# wiz16b8m4ct3_0_WIZ16B8M4CT3 register map
Vendor: Texas Instruments
Registers are 32-bit, read-write, reset 0x0 unless marked. A register's access mark holds for its fields unless they carry their own. Offsets are as the file gives them; [hi:lo] are bit positions; {n}, {i} and the like mark numbered series.

## wiz16b8m4ct3_0_WIZ16B8M4CT3 (part 4 of 12)
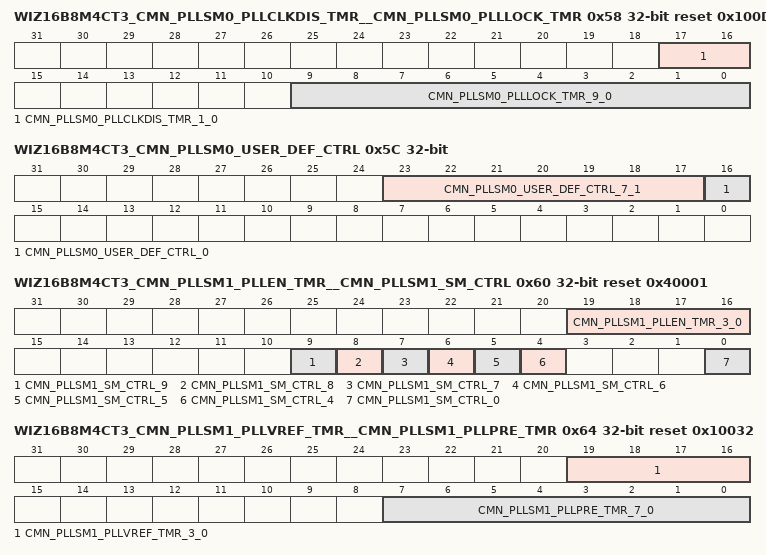
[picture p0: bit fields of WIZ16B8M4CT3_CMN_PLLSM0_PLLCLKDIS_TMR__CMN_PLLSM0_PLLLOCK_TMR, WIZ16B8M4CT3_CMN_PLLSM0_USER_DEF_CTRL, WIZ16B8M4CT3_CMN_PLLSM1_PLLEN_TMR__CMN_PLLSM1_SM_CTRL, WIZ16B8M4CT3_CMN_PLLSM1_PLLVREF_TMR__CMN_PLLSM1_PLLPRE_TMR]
0x58 WIZ16B8M4CT3_CMN_PLLSM0_PLLCLKDIS_TMR__CMN_PLLSM0_PLLLOCK_TMR reset 0x100D1
  [17:16] CMN_PLLSM0_PLLCLKDIS_TMR_1_0 — PLL clock disable delay state timer value : Value used for the timer when the startup state machine is in the PLL clock disable delay state. This timer delay is specified as the number of reference clocks to count.
  [9:0] CMN_PLLSM0_PLLLOCK_TMR_9_0 — PLL lock delay state timer value : Value used for the timer when the startup state machine is in the PLL lock delay state. This timer delay is specified as the number of reference clocks to count.
0x5C WIZ16B8M4CT3_CMN_PLLSM0_USER_DEF_CTRL
  [23:17] CMN_PLLSM0_USER_DEF_CTRL_7_1 — Reserved - spare
  [16] CMN_PLLSM0_USER_DEF_CTRL_0 — PLL lock override: When active (1'b1), this bit will force the PLL lock indication active.
0x60 WIZ16B8M4CT3_CMN_PLLSM1_PLLEN_TMR__CMN_PLLSM1_SM_CTRL reset 0x40001
  [19:16] CMN_PLLSM1_PLLEN_TMR_3_0 — PLL enable state timer value : Value used for the timer when the startup state machine is in the PLL enable state. This timer delay is specified as the number of reference clocks to count.
  [9] CMN_PLLSM1_SM_CTRL_9 — PLL enable override enable : When active (1'b1), the PLL enable override bit in this register will drive the pllsmda_pll_en pin from the PLLSM directly.
  [8] CMN_PLLSM1_SM_CTRL_8 — PLL enable override : When enabled by the PLL enable override enable bit in this register, this bit will drive the pllsmda_pll_en pin from the PLLSM directly.
  [7] CMN_PLLSM1_SM_CTRL_7 — PLL reset override enable : When active (1'b1), the PLL reset override bit in this register will drive the pllsmda_pll_rst_n pin from the PLLSM directly.
  [6] CMN_PLLSM1_SM_CTRL_6 — PLL reset override : When enabled by the PLL reset override enable bit in this register, this bit will drive the pllsmda_pll_rst_n pin from the PLLSM directly.
  [5] CMN_PLLSM1_SM_CTRL_5 — PLL pre charge override enable : When active (1'b1), the PLL pre charge override bit in this register will drive the pllsmda_pll_pre_charge pin from the PLLSM directly.
  [4] CMN_PLLSM1_SM_CTRL_4 — PLL pre charge override : When enabled by the PLL pre charge override enable bit in this register, this bit will drive the pllsmda_pll_pre_charge pin from the PLLSM directly.
  [0] CMN_PLLSM1_SM_CTRL_0 — Skip PLL re-calibration : When this bit is active (1'b1), the PLL calibration state will be skipped if it was previously run, unless the PLL is disabled or resetting the state machine.
0x64 WIZ16B8M4CT3_CMN_PLLSM1_PLLVREF_TMR__CMN_PLLSM1_PLLPRE_TMR reset 0x10032
  [19:16] CMN_PLLSM1_PLLVREF_TMR_3_0 — PLL VREF delay state timer value : Value used for the timer when the startup state machine is in the PLL VREF delay state. This timer delay is specified as the number of reference clocks to count.
  [7:0] CMN_PLLSM1_PLLPRE_TMR_7_0 — PLL pre-charge state timer value : Value used for the timer when the startup state machine is in the PLL pre-charge state. This timer delay is specified as the number of reference clocks to count.
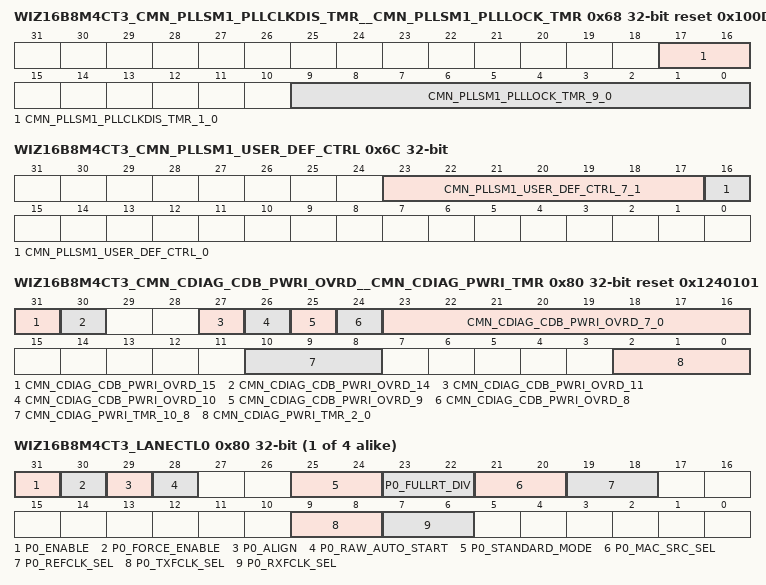
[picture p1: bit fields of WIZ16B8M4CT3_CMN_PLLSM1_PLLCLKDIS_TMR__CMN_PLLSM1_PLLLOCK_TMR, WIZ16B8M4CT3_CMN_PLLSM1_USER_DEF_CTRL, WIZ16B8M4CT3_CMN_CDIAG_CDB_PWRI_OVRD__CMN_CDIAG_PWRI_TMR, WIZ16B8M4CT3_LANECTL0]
0x68 WIZ16B8M4CT3_CMN_PLLSM1_PLLCLKDIS_TMR__CMN_PLLSM1_PLLLOCK_TMR reset 0x100D1
  [17:16] CMN_PLLSM1_PLLCLKDIS_TMR_1_0 — PLL clock disable delay state timer value : Value used for the timer when the startup state machine is in the PLL clock disable delay state. This timer delay is specified as the number of reference clocks to count.
  [9:0] CMN_PLLSM1_PLLLOCK_TMR_9_0 — PLL lock delay state timer value : Value used for the timer when the startup state machine is in the PLL lock delay state. This timer delay is specified as the number of reference clocks to count.
0x6C WIZ16B8M4CT3_CMN_PLLSM1_USER_DEF_CTRL
  [23:17] CMN_PLLSM1_USER_DEF_CTRL_7_1 — Reserved - spare
  [16] CMN_PLLSM1_USER_DEF_CTRL_0 — PLL lock override: When active (1'b1), this bit will force the PLL lock indication active.
0x80 WIZ16B8M4CT3_CMN_CDIAG_CDB_PWRI_OVRD__CMN_CDIAG_PWRI_TMR access per field reset 0x1240101
  [31] CMN_CDIAG_CDB_PWRI_OVRD_15 rw — Power island controller input override enable: When enabled, the power island control state machine input override bits in this register will drive the power island control state machine directly, and override any control from other state machines in the macro. Note: The CDB power island must be triggered to be enabled, by accessing a register outside of the common control module control and diagnostic registers space, prior to enabling this function. Note: This bit must never change state in the same register write that any of the override bits it controls in this register are changed. 1'b0: Override disabled 1'b1: Override enabled
  [30] CMN_CDIAG_CDB_PWRI_OVRD_14 rw — Power island controller output override enable: When enabled, the power island control state machine output override bits in this register will drive the power island control state machine outputs, and override any control from power island control state machine. Note: This bit must never change state in the same register write that any of the override bits it controls in this register are changed. 1'b0: Override disabled 1'b1: Override enabled
  [27] CMN_CDIAG_CDB_PWRI_OVRD_11 rw — Power suspend request override: When enabled, this bit will override the power_suspend_req input of the power island control state machine. Note: Whenever changing the state of this bit, no other CDB register access should be initiated for 1 uSec, to keep the CDB clock off while the power island state change transition is in progress.
  [26] CMN_CDIAG_CDB_PWRI_OVRD_10 ro — Power suspend acknowledge: This is the current state of the power_suspend_ack output from the power island control state machine. Note: This bit will always be set to 1'b1 after the power island is enabled, as a function of the power island controller input override enable bit in this register.
  [25] CMN_CDIAG_CDB_PWRI_OVRD_9 rw — Power recover request override: When enabled, this bit will override the power_recover_req input of the power island control state machine. Note: Whenever changing the state of this bit, no other CDB register access should be initiated for 1 uSec, to keep the CDB clock off while the power island state change transition is in progress.
  [24] CMN_CDIAG_CDB_PWRI_OVRD_8 ro — Power recover acknowledge: This is the current state of the power_recover_ack output from the power island control state machine. Note: This bit will always be set to 1'b1 after the power island is enabled, as a function of the power island controller input override enable bit in this register.
  [23:16] CMN_CDIAG_CDB_PWRI_OVRD_7_0 rw — Power island controller output override: When enabled, the bits in this field will override the output signals from the power island control state machine. The following are the power island control state machine output signals, and the bits in this field that they are associated with. Bit 7: state_sandh Bit 6: state_ret_save Bit 5: state_ret_restore (active low) Bit 4: power_en_ph_1 Bit 3: power_en_ph_2 Bit 2: power_isolation Bit 1: power_por_reset_n Bit 0: power_rstr_reset_n The default value of the bits in this register are such that the power island is not forced to be switched on when the power island controller output override enable bit in this register is enabled. When using this register to switch this power island on and off, the bits in this field are required to change in a specific order with individual register writes. The writes must happen in the order specified below. Note: When using this output override option in conditions when the reference clock is off, the CDB registers on the power island will only be readable, and latency will be much longer. The reason for this is the reference clock is normally used to synchronize control functions associated with this power island. Therefore these control functions will not proceed as they would in normal operation. This results in writes not being capable, and reads completing under the control of the watchdog timer.
  [10:8] CMN_CDIAG_PWRI_TMR_10_8 rw — Power enable phase 2 timer value: This specifies the number of reference clock cycles the power island control state machines in common will wait in the power phase 2 enable states, in order to allow enough time for the second phase of the switched domain to power up, before deactivating the isolation functions. The default value of this register corresponds to a delay of 40 nSec. Note: A value of 0 in this field is not valid, and will result in a delay of 1 clock cycle.
  [2:0] CMN_CDIAG_PWRI_TMR_2_0 rw — Power enable phase 1 timer value: This specifies the number of reference clock cycles the power island control state machines in common will wait in the power phase 1 enable states, in order to allow enough time for the first phase of the switched domain to power up, before enabling the second phase of the power up. The default value of this register corresponds to a delay of 40 nSec. Note: A value of 0 in this field is not valid, and will result in a delay of 1 clock cycle.
{0x80+0x40*i} WIZ16B8M4CT3_LANECTL{i} (i=0..3)
  [31] P{i}_ENABLE — The p{i}_enable is AND'd with the IPx_LNy_reset_n to enable the lane.
  [30] P{i}_FORCE_ENABLE — The p{i}_force_enable is OR'd with the IPx_LNy_reset_n to force enable the lane.
  [29] P{i}_ALIGN — The p{i}_align will auto align the RAW interface to 8B10B comma characters.
  [28] P{i}_RAW_AUTO_START — The p{i}_raw_auto_start will auto sequence the RAW interface according to the configuration settings
  [25:24] P{i}_STANDARD_MODE — Standard Mode specified by Cadence.
  [23:22] P{i}_FULLRT_DIV — Full Rate divider for 2x MAC speed mode. The PMA PLL full rate clock divider select - divide ratio for pma_pllclk_fullrt_ln_*. 00 = Divide by 1 01 = Divide by 2 10 = Divide by 4 11 = Divide by 8
  [21:20] P{i}_MAC_SRC_SEL — MAC clock source select : Selects which PMA clock to use as clock souse for pcs_mac_clk*_ln_*. 2'b00 - PMA output xcvr_pll_clk_fullrt_ln_* for the associated lane. 2'b01 - PMA output cmn_ref_clk_rcv. 2'b10 - PHY pma_cmn_refclk_int0. 2'b11 - PHY pma_cmn_refclk_int1.
  [19:18] P{i}_REFCLK_SEL — Refclk Select determines which clocks will be used for the IP refclk signal. 0 - pma_pllclk_fullrt_ln_{i} is used. 1 - pcs_mac_clk_ln_{i} is used. 2 - pcs_mac_clk_divx0_ln_{i} is used. 3 - pcs_mac_clk_divx1_ln_{i} is used.
  [9:8] P{i}_TXFCLK_SEL — Fclk Select determines which clocks will be used for the IP txfclk signal. 0 - pma_pllclk_fullrt_ln_{i} is used. 1 - pcs_mac_clk_ln_{i} is used. 2 - pcs_mac_clk_divx0_ln_{i} is used. 3 - pcs_mac_clk_divx1_ln_{i} is used.
  [7:6] P{i}_RXFCLK_SEL — Fclk Select determines which clocks will be used for the IP rxfclk signal. 0 - pma_rx_rd_clk2x_ln_{i} is used. 1 - pma_rx_rd_clk_ln_{i} is used. 2 - rd_div2_clk{i} is used. 3 - rd_div4_clk{i} is used.
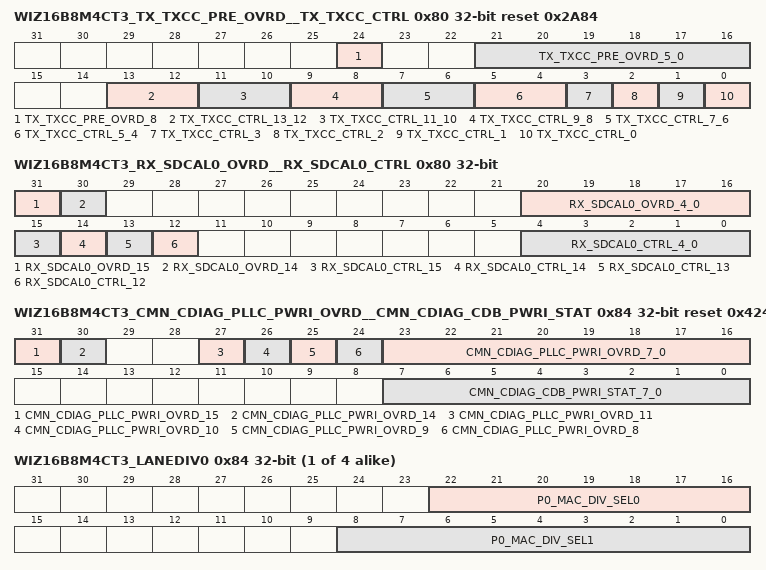
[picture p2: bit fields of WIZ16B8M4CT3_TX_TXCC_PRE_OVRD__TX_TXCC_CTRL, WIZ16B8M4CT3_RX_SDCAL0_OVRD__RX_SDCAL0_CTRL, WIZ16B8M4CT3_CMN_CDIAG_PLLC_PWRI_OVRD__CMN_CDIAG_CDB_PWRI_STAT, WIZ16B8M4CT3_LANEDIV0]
0x80 WIZ16B8M4CT3_TX_TXCC_PRE_OVRD__TX_TXCC_CTRL reset 0x2A84
  [24] TX_TXCC_PRE_OVRD_8 — Pre-cursor override enable: When enabled, the pre-cursor field in this register is used to override the pre-cursor value.
  [21:16] TX_TXCC_PRE_OVRD_5_0 — Pre-cursor override value: When enabled by the pre-cursor override enable bit in this register, the value in this field is used to override the pre-cursor value. Note: This field is 6 bits wide, to match the pre-cursor data input width on the tx_deemphasis input pin, only the least significant 5 bits are used to actually drive the H bridge driver controller. In the calculated modes, this will override the calculated pre-cursor value. Note : This register is for diagnostic purposes only. When this field is used, one must make sure that the value does not result in the H bridge driver controller input pin restrictions being violated. These restrictions are documented in the pin list of H bridge driver controller specification.
  [13:12] TX_TXCC_CTRL_13_12 — Margin multiplier rounding control: This field controls the rounding function on the margin multiplier. 2'b00 : Round to nearest integer 2'b01 : Floor 2'b10 : Ceiling
  [11:10] TX_TXCC_CTRL_11_10 — LF value multiplier rounding control: This field controls the rounding function on the LF value multiplier. 2'b00 : Round to nearest integer 2'b01 : Floor 2'b10 : Ceiling
  [9:8] TX_TXCC_CTRL_9_8 — Calculated post-emphasis multiplier rounding control: This field controls the rounding function on the calculated post-emphasis multiplier. 2'b00 : Round to nearest integer 2'b01 : Floor 2'b10 : Ceiling
  [7:6] TX_TXCC_CTRL_7_6 — Calculated pre-emphasis multiplier rounding control: This field controls the rounding function on the pre-emphasis multiplier. 2'b00 : Round to nearest integer 2'b01 : Floor 2'b10 : Ceiling
  [5:4] TX_TXCC_CTRL_5_4 — Coefficient calculator multiplier rounding control: This field controls the rounding function on the coefficient calculator multiplier. 2'b00 : Round to nearest integer 2'b01 : Floor 2'b10 : Ceiling
  [3] TX_TXCC_CTRL_3 — De-emphasis control standard mode 3 value: This bit controls the de-emphasis mode when the xcvr_standard_mode is set to 2'b11. 1'b0 : Use the calculated de-emphasis values based on the 2 least significant bits of the top level tx_deemphasis signal. 1'b1 : Use the coefficient values on all 18 bits of the top level tx_deemphasis signal.
  [2] TX_TXCC_CTRL_2 — De-emphasis control standard mode 2 value: This bit controls the de-emphasis mode when the xcvr_standard_mode is set to 2'b10. 1'b0 : Use the calculated de-emphasis values based on the 2 least significant bits of the top level tx_deemphasis signal. 1'b1 : Use the coefficient values on all 18 bits of the top level tx_deemphasis signal.
  [1] TX_TXCC_CTRL_1 — De-emphasis control standard mode 1 value: This bit controls the de-emphasis mode when the xcvr_standard_mode is set to 2'b01. 1'b0 : Use the calculated de-emphasis values based on the 2 least significant bits of the top level tx_deemphasis signal. 1'b1 : Use the coefficient values on all 18 bits of the top level tx_deemphasis signal.
  [0] TX_TXCC_CTRL_0 — De-emphasis control standard mode 0 value: This bit controls the de-emphasis mode when the xcvr_standard_mode is set to 2'b00. 1'b0 : Use the calculated de-emphasis values based on the 2 least significant bits of the top level tx_deemphasis signal. 1'b1 : Use the coefficient values on all 18 bits of the top level tx_deemphasis signal.
0x80 WIZ16B8M4CT3_RX_SDCAL0_OVRD__RX_SDCAL0_CTRL access per field
  [31] RX_SDCAL0_OVRD_15 rw — Calibration code override enable: Activation (1'b1) of this register bit allows the codes determined during the automatic calibration process to be overridden. The override value is specified using the calibration code override value field of this register.
  [30] RX_SDCAL0_OVRD_14 rw — Analog calibration enable override: Activation (1'b1) of this register bit will force the analog calibration circuits to be enabled by activating the rxda_sd_cal_0_en enable and the rxda_sd_cal_0_clk clock.
  [20:16] RX_SDCAL0_OVRD_4_0 rw — Calibration code override value: These bits are used to override the calibration code determined during the automatic calibration process. The code written to these bits is valid when the calibration code override enable bit in this register is active. The codes in this field correspond to those described in the calibration code field in the Signal detect calibration 0 control register (!) on page 232.
  [15] RX_SDCAL0_CTRL_15 rw — Start calibration: Activating (1'b1) this bit will start the calibration process. This signal must remain active until the calibration process is complete. To start another calibration process, this register must first be set inactive (1'b0) until the bandbap calibration process done bit in this register is cleared. Note: This bit is intended to be for diagnostics purposes only. This calibration process is automatically activated internally by the power state machine. When using this bit, the user must wait until after the internally activated process completes.
  [14] RX_SDCAL0_CTRL_14 ro — Calibration process done: This bit will be set to 1'b1 when the calibration process is complete. It will be cleared by cmn_reset_n, or by the deactivation of the start calibration bit in this register after calibration is complete. Note: This bit is intended to be for diagnostics purposes only. Note: This bit is not likely to be observed as being set after internal automatic calibration is complete, because the internally generated run signal will be driven inactive immediately after the done signal is activated, and therefore the internal done signal will be cleared. Note: Three cmn_ref_clk cycles are required after the start of the calibration process to clear this signal.
  [13] RX_SDCAL0_CTRL_13 ro — No analog calibration response : This signal indicates that the calibration function has gone through the entire calibration process, reached the final calibration value, and the analog has not responded indicating that a valid calibration value has been reached. Note: Due to the nature of the calibration process, it is not possible to determine if the analog responded or not for the lowest code of 4'b1001. The reason for this is, when sequencing to lower codes, the calibration function is looking for the analog response to transition from 1'b1 to 1'b0. If the lowest calibration code is the correct code, the analog will respond with 1'b1, and the algorithm can't sequence to a lower code to look for the transition from 1'b1 to 1'b0. Similarly, if the analog is not responding, it is not possible to sequence to a lower code to detect this. Therefore, even when the calibration function selects this calibration code as valid, this bit will be set.
  [12] RX_SDCAL0_CTRL_12 ro — Current analog comparator response: This is the current state of the analog comparator response signal (rxda_sd_cal_0_comp). This signal is not synchronized, and is provided for diagnostic purposes only.
  [4:0] RX_SDCAL0_CTRL_4_0 ro — Calibration code: This is the calibration code that was determined by the calibration process. The following indicates how this encoding maps to the rxda_sd_cal_0_up and rxda_sd_cal_0_code signals going to the analog function. The five bit value on the left is the value of this field. The one bit value on the right corresponds to the value of rxda_sd_cal_0_up. The four bit field corresponds to the value of rxda_sd_cal_0_code. 5'b01111 : 1'b1, 4'b1111 5'b01110 : 1'b1, 4'b1110 ... 5'b00010 : 1'b1, 4'b0010 5'b00001 : 1'b1, 4'b0001 5'b00000 : 1'b1, 4'b0000 5'b11111 : 1'b0, 4'b0001 5'b11110 : 1'b0, 4'b0010 ... 5'b10010 : 1'b0, 4'b1110 5'b10001 : 1'b0, 4'b1111
0x84 WIZ16B8M4CT3_CMN_CDIAG_PLLC_PWRI_OVRD__CMN_CDIAG_CDB_PWRI_STAT access per field reset 0x424003B
  [31] CMN_CDIAG_PLLC_PWRI_OVRD_15 rw — Power island controller input override enable: When enabled, the power island control state machine input override bits in this register will drive the power island control state machine directly, and override any control from other state machines in the macro. Note: The CDB power island must be triggered to be enabled, by accessing a register outside of the common control module control and diagnostic registers space, prior to enabling this function. Note: This bit must never change state in the same register write that any of the override bits it controls in this register are changed. 1'b0: Override disabled 1'b1: Override enabled
  [30] CMN_CDIAG_PLLC_PWRI_OVRD_14 rw — Power island controller output override enable: When enabled, the power island control state machine output override bits in this register will drive the power island control state machine outputs, and override any control from power island control state machine. Note: This bit must never change state in the same register write that any of the override bits it controls in this register are changed. 1'b0: Override disabled 1'b1: Override enabled
  [27] CMN_CDIAG_PLLC_PWRI_OVRD_11 rw — Power suspend request override: When enabled, this bit will override the power_suspend_req input of the power island control state machine.
  [26] CMN_CDIAG_PLLC_PWRI_OVRD_10 ro — Power suspend acknowledge: This is the current state of the power_suspend_ack output from the power island control state machine. Note: This bit will always be set to 1'b1 after the power island is enabled, as a function of the power island controller input override enable bit in this register.
  [25] CMN_CDIAG_PLLC_PWRI_OVRD_9 rw — Power recover request override: When enabled, this bit will override the power_recover_req input of the power island control state machine.
  [24] CMN_CDIAG_PLLC_PWRI_OVRD_8 ro — Power recover acknowledge: This is the current state of the power_recover_ack output from the power island control state machine. Note: This bit will always be set to 1'b1 after the power island is enabled, as a function of the power island controller input override enable bit in this register.
  [23:16] CMN_CDIAG_PLLC_PWRI_OVRD_7_0 rw — Power island controller output override: When enabled, the bits in this field will override the output signals from the power island control state machine. The following are the power island control state machine output signals, and the bits in this field that they are associated with. Bit 7: state_sandh Bit 6: state_ret_save Bit 5: state_ret_restore (active low) Bit 4: power_en_ph_1 Bit 3: power_en_ph_2 Bit 2: power_isolation Bit 1: power_por_reset_n Bit 0: power_rstr_reset_n The default value of the bits in this register are such that the power island is not forced to be switched on when the power island controller output override enable bit in this register is enabled. When using this register to switch this power island on and off, the bits in this field are required to change in a specific order with individual register writes. The writes must happen in the order specified below. 8'b00100100 : Power island is not being forced on 8'b10100100 8'b10110100 8'b10111100 8'b10111111 8'b10111011 8'b00111011 : Power island is being forced on 8'b10111011 8'b10111111 8'b11111111 8'b10111111 8'b10111110 8'b10100110 : Power island is being forced off, and in state retention 8'b10110110 8'b10111110 8'b10111111 8'b10011111 8'b10111111 8'b10111011 8'b00111011 : Power island is being forced on, with state restored
  [7:0] CMN_CDIAG_CDB_PWRI_STAT_7_0 ro — Power island controller output status: This field indicates the current state of the output signals from the power island control state machine. The following are the power island control state machine output signals, and the bits in this field that they are associated with. Bit 7: state_sandh Bit 6: state_ret_save Bit 5: state_ret_restore (active low) Bit 4: power_en_ph_1 Bit 3: power_en_ph_2 Bit 2: power_isolation Bit 1: power_por_reset_n Bit 0: power_rstr_reset_n
{0x84+0x40*i} WIZ16B8M4CT3_LANEDIV{i} (i=0..3)
  [22:16] P{i}_MAC_DIV_SEL0 — The ~ip{i}_mac_div_sel0 controls the divider for lane {i} MAC clock divider ratio select : Selects the divider ratio for pcs_mac_clk_divx0_ln_*. 7'd0 : Reserved 7'd1 : Divide by 1 7'd2 : Divide by 2 7'd3 : Divide by 3 ... 7'dn : Divide by n n = 127 (maximum)
  [8:0] P{i}_MAC_DIV_SEL1 — The ~ip{i}_mac_div_sel1 controls the divider for lane {i} MAC clock divider ratio select : Selects the divider ratio for pcs_mac_clk_divx1_ln_*. 9'd0 : Reserved 9'd1 : Divide by 1 9'd2 : Divide by 2 9'd3 : Divide by 3 ... 9'dn : Divide by n n = 511 (maximum)
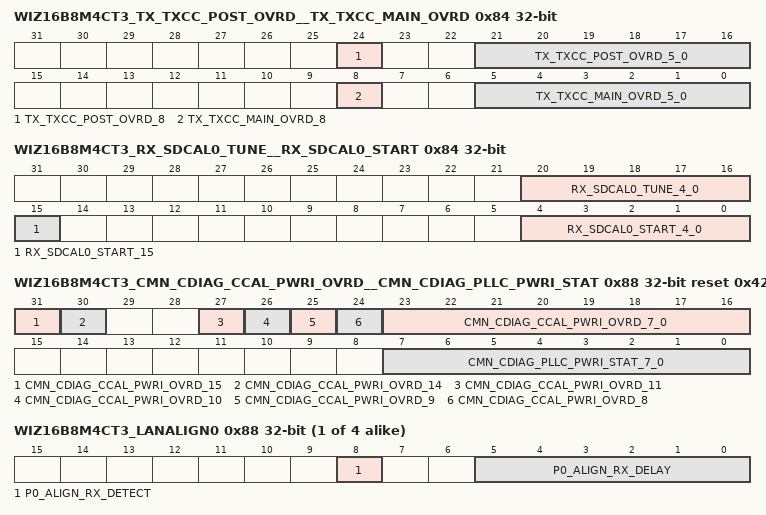
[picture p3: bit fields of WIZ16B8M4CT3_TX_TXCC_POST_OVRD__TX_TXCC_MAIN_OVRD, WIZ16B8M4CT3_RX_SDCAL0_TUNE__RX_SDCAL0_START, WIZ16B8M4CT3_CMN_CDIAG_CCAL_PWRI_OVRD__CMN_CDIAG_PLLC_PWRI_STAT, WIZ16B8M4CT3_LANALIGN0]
0x84 WIZ16B8M4CT3_TX_TXCC_POST_OVRD__TX_TXCC_MAIN_OVRD
  [24] TX_TXCC_POST_OVRD_8 — Post-cursor override enable: When enabled, the post-cursor field in this register is used to override the post-cursor value.
  [21:16] TX_TXCC_POST_OVRD_5_0 — Post-cursor override value: When enabled by the post-cursor override enable bit in this register, the value in this field is used to override the post-cursor value. Note: This field is 6 bits wide, to match the post-cursor data input width on the tx_deemphasis input pin, only the least significant 5 bits are used to actually drive the H bridge driver controller. In the calculated modes, this will override the calculated post-cursor value. Note : This register is for diagnostic purposes only. When this field is used, one must make sure that the value does not result in the H bridge driver controller input pin restrictions being violated. These restrictions are documented in the pin list of H bridge driver controller specification.
  [8] TX_TXCC_MAIN_OVRD_8 — Main-cursor override enable: When enabled, the main-cursor field in this register is used to override the main-cursor value.
  [5:0] TX_TXCC_MAIN_OVRD_5_0 — Main-cursor override value: When enabled by the main-cursor override enable bit in this register, the value in this field is used to override the main-cursor value. Note: This field is 6 bits wide, to match the main-cursor data input width on the tx_deemphasis input pin, only the least significant 5 bits are used to actually drive the H bridge driver controller. In the calculated modes, this will override the calculated main-cursor value. Note : This register is for diagnostic purposes only. When this field is used, one must make sure that the value does not result in the H bridge driver controller input pin restrictions being violated. These restrictions are documented in the pin list of H bridge driver controller specification.
0x84 WIZ16B8M4CT3_RX_SDCAL0_TUNE__RX_SDCAL0_START
  [20:16] RX_SDCAL0_TUNE_4_0 — Calibration tune value: The value of this field is added to the automatically calibrated code, or the override code if override is enabled. Note: This value is a twos complement value, so the calibrated code can be increased or decreased.
  [15] RX_SDCAL0_START_15 — Calibration direction: This controls the direction that the automatic calibration process steps the calibration codes in. 1'b0 : From 5'b10001 to 5'b01111. 1'b1 : From 5'b01111 to 5'b00000.
  [4:0] RX_SDCAL0_START_4_0 — Start calibration code: This is the calibration code that the calibration process starts with when automatic calibration is run. The codes in this field correspond to those described in the calibration code field in the Signal detect calibration 0 control register (!) on page 232.
0x88 WIZ16B8M4CT3_CMN_CDIAG_CCAL_PWRI_OVRD__CMN_CDIAG_PLLC_PWRI_STAT access per field reset 0x4240024
  [31] CMN_CDIAG_CCAL_PWRI_OVRD_15 rw — Power island controller input override enable: When enabled, the power island control state machine input override bits in this register will drive the power island control state machine directly, and override any control from other state machines in the macro. Note: The CDB power island must be triggered to be enabled, by accessing a register outside of the common control module control and diagnostic registers space, prior to enabling this function. Note: This bit must never change state in the same register write that any of the override bits it controls in this register are changed. 1'b0: Override disabled 1'b1: Override enabled
  [30] CMN_CDIAG_CCAL_PWRI_OVRD_14 rw — Power island controller output override enable: When enabled, the power island control state machine output override bits in this register will drive the power island control state machine outputs, and override any control from power island control state machine. Note: This bit must never change state in the same register write that any of the override bits it controls in this register are changed. 1'b0: Override disabled 1'b1: Override enabled
  [27] CMN_CDIAG_CCAL_PWRI_OVRD_11 rw — Power suspend request override: When enabled, this bit will override the power_suspend_req input of the power island control state machine.
  [26] CMN_CDIAG_CCAL_PWRI_OVRD_10 ro — Power suspend acknowledge: This is the current state of the power_suspend_ack output from the power island control state machine. Note: This bit will always be set to 1'b1 after the power island is enabled, as a function of the power island controller input override enable bit in this register.
  [25] CMN_CDIAG_CCAL_PWRI_OVRD_9 rw — Power recover request override: When enabled, this bit will override the power_recover_req input of the power island control state machine.
  [24] CMN_CDIAG_CCAL_PWRI_OVRD_8 ro — Power recover acknowledge: This is the current state of the power_recover_ack output from the power island control state machine. Note: This bit will always be set to 1'b1 after the power island is enabled, as a function of the power island controller input override enable bit in this register.
  [23:16] CMN_CDIAG_CCAL_PWRI_OVRD_7_0 rw — Power island controller output override: When enabled, the bits in this field will override the output signals from the power island control state machine. The following are the power island control state machine output signals, and the bits in this field that they are associated with. Bit 7: state_sandh Bit 6: state_ret_save Bit 5: state_ret_restore (active low) Bit 4: power_en_ph_1 Bit 3: power_en_ph_2 Bit 2: power_isolation Bit 1: power_por_reset_n Bit 0: power_rstr_reset_n The default value of the bits in this register are such that the power island is not forced to be switched on when the power island controller output override enable bit in this register is enabled. When using this register to switch this power island on and off, the bits in this field are required to change in a specific order with individual register writes. The writes must happen in the order specified below. 8'b00100100 : Power island is not being forced on 8'b10100100 8'b10110100 8'b10111100 8'b10111111 8'b10111011 8'b00111011 : Power island is being forced on 8'b10111011 8'b10111111 8'b11111111 8'b10111111 8'b10111110 8'b10100110 : Power island is being forced off, and in state retention 8'b10110110 8'b10111110 8'b10111111 8'b10011111 8'b10111111 8'b10111011 8'b00111011 : Power island is being forced on, with state restored
  [7:0] CMN_CDIAG_PLLC_PWRI_STAT_7_0 ro — Power island controller output status: This field indicates the current state of the output signals from the power island control state machine. The following are the power island control state machine output signals, and the bits in this field that they are associated with. Bit 7: state_sandh Bit 6: state_ret_save Bit 5: state_ret_restore (active low) Bit 4: power_en_ph_1 Bit 3: power_en_ph_2 Bit 2: power_isolation Bit 1: power_por_reset_n Bit 0: power_rstr_reset_n
{0x88+0x40*i} WIZ16B8M4CT3_LANALIGN{i} ro (i=0..3)
  [8] P{i}_ALIGN_RX_DETECT — The ~ip{i}_align_rx_detect indicates that alignment has happened and The ~ip{i}_align_rx_delay is valid.
  [5:0] P{i}_ALIGN_RX_DELAY — The ~ip{i}_align_rx_delay indicates the number of bits that are added to align the data to an 8B10B alignment. This value should be added to the latency of the receiver so that an accurate time of Time Sync packets can be calculated.
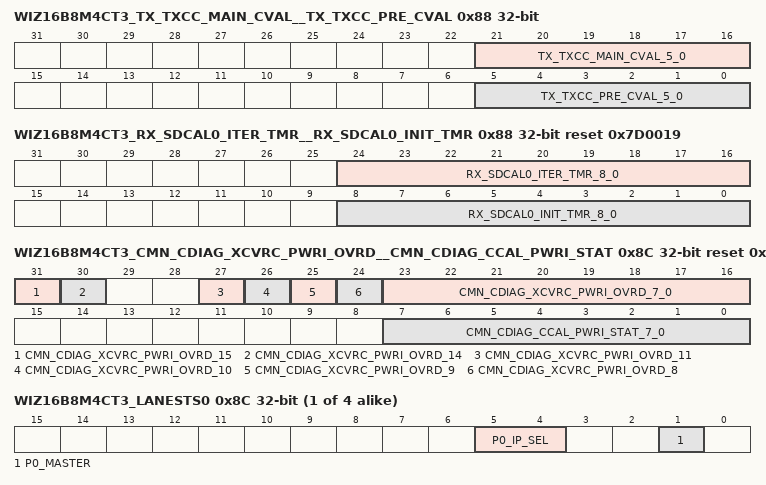
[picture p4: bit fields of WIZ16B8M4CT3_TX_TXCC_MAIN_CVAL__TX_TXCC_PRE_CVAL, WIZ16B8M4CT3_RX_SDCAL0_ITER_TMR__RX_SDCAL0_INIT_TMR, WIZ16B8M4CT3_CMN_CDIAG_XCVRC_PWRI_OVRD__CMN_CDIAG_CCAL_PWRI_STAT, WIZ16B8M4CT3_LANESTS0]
0x88 WIZ16B8M4CT3_TX_TXCC_MAIN_CVAL__TX_TXCC_PRE_CVAL ro
  [21:16] TX_TXCC_MAIN_CVAL_5_0 — Main-cursor value: The value in this field indicates the current value of the main-cursor (C0) coefficient. The value of this field can be any of the following, depending on the current mode of operation. The override value when override is enabled, under the control of the TX main-cursor override register on page 179 The main-cursor data on the tx_deemphasis input pin when the calculated de-emphasis values are disabled, under the control of the TX coefficient controller control register on page 178. All 0s when the calculated de-emphasis values are enabled, under the control of the TX coefficient controller control register on page 178. Note: The value of this is a function of input values and internal logic. Therefore, there is not a fixed reset value.
  [5:0] TX_TXCC_PRE_CVAL_5_0 — Pre-cursor value: The value in this field indicates the current value of the pre-cursor (C-1) coefficient. The value of this field can be any of the following, depending on the current mode of operation. The override value when override is enabled, under the control of the TX pre-cursor override register on page 179 The pre-cursor data on the tx_deemphasis input pin when the calculated de-emphasis values are disabled, under the control of the TX coefficient controller control register on page 178. The internally calculated pre-cursor value when the calculated de-emphasis values are enabled, under the control of the TX coefficient controller control register on page 178. Note: The value of this is a function of input values and internal logic. Therefore, there is not a fixed reset value.
0x88 WIZ16B8M4CT3_RX_SDCAL0_ITER_TMR__RX_SDCAL0_INIT_TMR reset 0x7D0019
  [24:16] RX_SDCAL0_ITER_TMR_8_0 — Iteration wait timer value: This is the number of cmn_ref_clk clocks to wait between when a value is placed on the calibration code signals going to the analog, and when the comparator value coming from the analog circuits can be checked. Note: This results in the minimum number of cmn_ref_clk clocks required to wait 5 uSec. Note: This should never be set to a value of less than 3.
  [8:0] RX_SDCAL0_INIT_TMR_8_0 — Initialization wait timer value: This is the number of cmn_ref_clk clocks to wait between when the analog calibration circuits are enabled, and when the first values are placed on the calibration code signals going to the analog. Note: This results in the minimum number of cmn_ref_clk clocks required to wait 1 uSec. Note: This should never be set to a value of less than 1.
0x8C WIZ16B8M4CT3_CMN_CDIAG_XCVRC_PWRI_OVRD__CMN_CDIAG_CCAL_PWRI_STAT access per field reset 0x4240024
  [31] CMN_CDIAG_XCVRC_PWRI_OVRD_15 rw — Power island controller input override enable: When enabled, the power island control state machine input override bits in this register will drive the power island control state machine directly, and override any control from other state machines in the macro. Note: The CDB power island must be triggered to be enabled, by accessing a register outside of the common control module control and diagnostic registers space, prior to enabling this function. Note: This bit must never change state in the same register write that any of the override bits it controls in this register are changed. 1'b0: Override disabled 1'b1: Override enabled
  [30] CMN_CDIAG_XCVRC_PWRI_OVRD_14 rw — Power island controller output override enable: When enabled, the power island control state machine output override bits in this register will drive the power island control state machine outputs, and override any control from power island control state machine. Note: This bit must never change state in the same register write that any of the override bits it controls in this register are changed. 1'b0: Override disabled 1'b1: Override enabled
  [27] CMN_CDIAG_XCVRC_PWRI_OVRD_11 rw — Power suspend request override: When enabled, this bit will override the power_suspend_req input of the power island control state machine.
  [26] CMN_CDIAG_XCVRC_PWRI_OVRD_10 ro — Power suspend acknowledge: This is the current state of the power_suspend_ack output from the power island control state machine. Note: This bit will always be set to 1'b1 after the power island is enabled, as a function of the power island controller input override enable bit in this register.
  [25] CMN_CDIAG_XCVRC_PWRI_OVRD_9 rw — Power recover request override: When enabled, this bit will override the power_recover_req input of the power island control state machine.
  [24] CMN_CDIAG_XCVRC_PWRI_OVRD_8 ro — Power recover acknowledge: This is the current state of the power_recover_ack output from the power island control state machine. Note: This bit will always be set to 1'b1 after the power island is enabled, as a function of the power island controller input override enable bit in this register.
  [23:16] CMN_CDIAG_XCVRC_PWRI_OVRD_7_0 rw — Power island controller output override: When enabled, the bits in this field will override the output signals from the power island control state machine. The following are the power island control state machine output signals, and the bits in this field that they are associated with. Bit 7: state_sandh Bit 6: state_ret_save Bit 5: state_ret_restore (active low) Bit 4: power_en_ph_1 Bit 3: power_en_ph_2 Bit 2: power_isolation Bit 1: power_por_reset_n Bit 0: power_rstr_reset_n The default value of the bits in this register are such that the power island is not forced to be switched on when the power island controller output override enable bit in this register is enabled. When using this register to switch this power island on and off, the bits in this field are required to change in a specific order with individual register writes. The writes must happen in the order specified below. 8'b00100100 : Power island is not being forced on 8'b10100100 8'b10110100 8'b10111100 8'b10111111 8'b10111011 8'b00111011 : Power island is being forced on 8'b10111011 8'b10111111 8'b11111111 8'b10111111 8'b10111110 8'b10100110 : Power island is being forced off, and in state retention 8'b10110110 8'b10111110 8'b10111111 8'b10011111 8'b10111111 8'b10111011 8'b00111011 : Power island is being forced on, with state restored
  [7:0] CMN_CDIAG_CCAL_PWRI_STAT_7_0 ro — Power island controller output status: This field indicates the current state of the output signals from the power island control state machine. The following are the power island control state machine output signals, and the bits in this field that they are associated with. Bit 7: state_sandh Bit 6: state_ret_save Bit 5: state_ret_restore (active low) Bit 4: power_en_ph_1 Bit 3: power_en_ph_2 Bit 2: power_isolation Bit 1: power_por_reset_n Bit 0: power_rstr_reset_n
{0x8C+0x40*i} WIZ16B8M4CT3_LANESTS{i} ro (i=0..3)
  [5:4] P{i}_IP_SEL — The ~ip{i}_ip_sel indicates the current IP lane selection for the lane.
  [1] P{i}_MASTER — The ~ip{i}_master indicates the lane is a base lane for a multi lane link. When '1' Lane is lane 0 of a multi lane link, When '0' lane is part of a multi lane link.
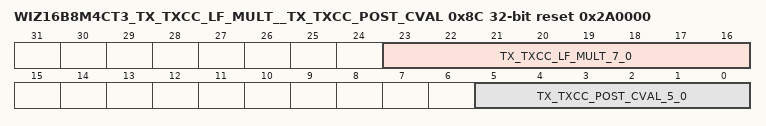
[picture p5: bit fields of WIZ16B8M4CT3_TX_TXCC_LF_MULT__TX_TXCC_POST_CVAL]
0x8C WIZ16B8M4CT3_TX_TXCC_LF_MULT__TX_TXCC_POST_CVAL access per field reset 0x2A0000
  [23:16] TX_TXCC_LF_MULT_7_0 rw — LF multiplier value: The value in this field specifies the multiplier value used to generate the LF value from the FS value. The following describes the multiplier value each bit in this field corresponds to. Bit 7 : 128/128 = 1.000000 Bit 6 : 64/128 = 0.500000 Bit 5 : 32/128 = 0.250000 Bit 4 : 16/128 = 0.125000 Bit 3 : 8/128 = 0.062500 Bit 2 : 4/128 = 0.031250 Bit 1 : 2/128 = 0.015625 Bit 0 : 1/128 = 0.0078125 Note: The output of the multiplier is 6 bits wide. It is possible to set the multiplier value here to a sufficiently large value to cause the multiplier result to be such that it can't be represented by a 6 bit value. In such a case, the multiplier output will be driven to 6'b111111.
  [5:0] TX_TXCC_POST_CVAL_5_0 ro — Post-cursor value: The value in this field indicates the current value of the post-cursor (C+1) coefficient. The value of this field can be any of the following, depending on the current mode of operation. The override value when override is enabled, under the control of the TX post-cursor override register on page 179 The post-cursor data on the tx_deemphasis input pin when the calculated de-emphasis values are disabled, under the control of the TX coefficient controller control register on page 178. The internally calculated post-cursor value when the calculated de-emphasis values are enabled, under the control of the TX coefficient controller control register on page 178. Note: The value of this is a function of input values and internal logic. Therefore, there is not a fixed reset value.
